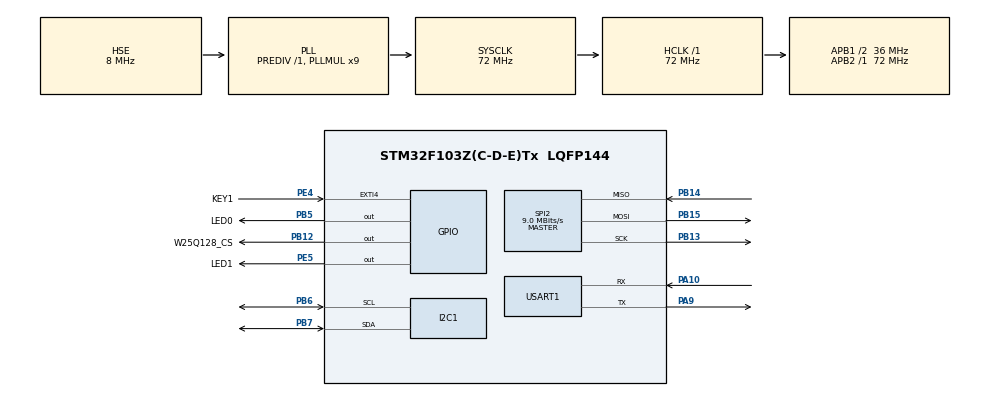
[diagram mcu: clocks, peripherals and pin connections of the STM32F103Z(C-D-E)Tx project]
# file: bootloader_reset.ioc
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Mcu.Family=STM32F1
Mcu.Name=STM32F103Z(C-D-E)Tx
Mcu.Package=LQFP144
NVIC.EXTI4_IRQn=true\:4\:0\:true\:false\:true\:true\:true\:true
NVIC.PriorityGroup=NVIC_PRIORITYGROUP_4
NVIC.USART1_IRQn=true\:5\:0\:true\:false\:true\:true\:true\:true
OSC_IN.Mode=HSE-External-Oscillator
OSC_IN.Signal=RCC_OSC_IN
OSC_OUT.Mode=HSE-External-Oscillator
OSC_OUT.Signal=RCC_OSC_OUT
PA10.Mode=Asynchronous
PA10.Signal=USART1_RX
PA13.Mode=Serial_Wire
PA13.Signal=SYS_JTMS-SWDIO
PA14.Mode=Serial_Wire
PA14.Signal=SYS_JTCK-SWCLK
PA9.Mode=Asynchronous
PA9.Signal=USART1_TX
PB12.GPIO_Label=W25Q128_CS
PB12.GPIO_Speed=GPIO_SPEED_FREQ_HIGH
PB12.PinState=GPIO_PIN_SET
PB12.Signal=GPIO_Output
PB13.Mode=Full_Duplex_Master
PB13.Signal=SPI2_SCK
PB14.Mode=Full_Duplex_Master
PB14.Signal=SPI2_MISO
PB15.Mode=Full_Duplex_Master
PB15.Signal=SPI2_MOSI
PB5.GPIO_Label=LED0
PB5.GPIO_Speed=GPIO_SPEED_FREQ_HIGH
PB5.PinState=GPIO_PIN_SET
PB5.Signal=GPIO_Output
PB6.Mode=I2C
PB6.Signal=I2C1_SCL
PB7.Mode=I2C
PB7.Signal=I2C1_SDA
PC14-OSC32_IN.Mode=LSE-External-Oscillator
PC14-OSC32_IN.Signal=RCC_OSC32_IN
PC15-OSC32_OUT.Mode=LSE-External-Oscillator
PC15-OSC32_OUT.Signal=RCC_OSC32_OUT
PE4.GPIO_Label=KEY1
PE4.GPIO_ModeDefaultEXTI=GPIO_MODE_IT_FALLING
PE4.GPIO_PuPd=GPIO_PULLUP
PE4.Signal=GPXTI4
PE5.GPIO_Label=LED1
PE5.GPIO_Speed=GPIO_SPEED_FREQ_HIGH
PE5.PinState=GPIO_PIN_SET
PE5.Signal=GPIO_Output
ProjectManager.HeapSize=0x200
ProjectManager.StackSize=0x400
ProjectManager.TargetToolchain=MDK-ARM V5.32
RCC.AHBFreq_Value=72000000
RCC.APB1CLKDivider=RCC_HCLK_DIV2
RCC.APB1Freq_Value=36000000
RCC.APB1TimFreq_Value=72000000
RCC.APB2Freq_Value=72000000
RCC.APB2TimFreq_Value=72000000
RCC.HCLKFreq_Value=72000000
RCC.PLLMUL=RCC_PLL_MUL9
RCC.PLLSourceVirtual=RCC_PLLSOURCE_HSE
RCC.SYSCLKFreq_VALUE=72000000
RCC.SYSCLKSource=RCC_SYSCLKSOURCE_PLLCLK
RCC.USBFreq_Value=72000000
SPI2.BaudRatePrescaler=SPI_BAUDRATEPRESCALER_4
SPI2.CalculateBaudRate=9.0 MBits/s
SPI2.Direction=SPI_DIRECTION_2LINES
SPI2.Mode=SPI_MODE_MASTER
SPI2.VirtualType=VM_MASTER
USART1.VirtualMode=VM_ASYNC
board=custom

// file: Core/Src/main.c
/* USER CODE BEGIN Header */
/**
 ******************************************************************************
 * @file           : main.c
 * @brief          : Main program body
 ******************************************************************************
 * @attention
 *
 * Copyright (c) 2026 STMicroelectronics.
 * All rights reserved.
 *
 * This software is licensed under terms that can be found in the LICENSE file
 * in the root directory of this software component.
 * If no LICENSE file comes with this software, it is provided AS-IS.
 *
 ******************************************************************************
 */
/* USER CODE END Header */
#include "main.h"
#include "i2c.h"
#include "spi.h"
#include "usart.h"
#include "gpio.h"

/* USER CODE BEGIN Includes */
// #include "App_bootloader.h"
#include "App_reset.h"
/* USER CODE END Includes */

void SystemClock_Config(void);

/* USER CODE BEGIN 0 */
#define RESET_ADDR 0x4000
/* USER CODE END 0 */

int main(void)
{

  /* USER CODE BEGIN 1 */
  // 重定向中断向量表
  SCB->VTOR = FLASH_BASE | RESET_ADDR;
  // 打开中断
  __enable_irq();
  /* USER CODE END 1 */

  /* MCU Configuration--------------------------------------------------------*/

  /* Reset of all peripherals, Initializes the Flash interface and the Systick. */
  HAL_Init();

  /* Configure the system clock */
  SystemClock_Config();

  /* Initialize all configured peripherals */
  MX_GPIO_Init();
  MX_USART1_UART_Init();
  MX_I2C1_Init();
  MX_SPI2_Init();
  /* USER CODE BEGIN 2 */

  // 出厂设置的默认程序
  App_bootloader_init();

  /* USER CODE END 2 */

  /* Infinite loop */
  /* USER CODE BEGIN WHILE */
  while (1)
  {

    App_bootloader_work();
    // 点亮LED0，表示正在运行出厂默认程序
    HAL_GPIO_WritePin(LED0_GPIO_Port, LED0_Pin, GPIO_PIN_RESET);
    HAL_Delay(100);
    HAL_GPIO_WritePin(LED0_GPIO_Port, LED0_Pin, GPIO_PIN_SET);
    HAL_Delay(100);
    /* USER CODE END WHILE */

  }
}

void SystemClock_Config(void)
{
  RCC_OscInitTypeDef RCC_OscInitStruct = {0};
  RCC_ClkInitTypeDef RCC_ClkInitStruct = {0};

  /** Initializes the RCC Oscillators according to the specified parameters
   * in the RCC_OscInitTypeDef structure.
   */
  RCC_OscInitStruct.OscillatorType = RCC_OSCILLATORTYPE_HSE;
  RCC_OscInitStruct.HSEState = RCC_HSE_ON;
  RCC_OscInitStruct.HSEPredivValue = RCC_HSE_PREDIV_DIV1;
  RCC_OscInitStruct.HSIState = RCC_HSI_ON;
  RCC_OscInitStruct.PLL.PLLState = RCC_PLL_ON;
  RCC_OscInitStruct.PLL.PLLSource = RCC_PLLSOURCE_HSE;
  RCC_OscInitStruct.PLL.PLLMUL = RCC_PLL_MUL9;
  if (HAL_RCC_OscConfig(&RCC_OscInitStruct) != HAL_OK)
  {
    Error_Handler();
  }

  /** Initializes the CPU, AHB and APB buses clocks
   */
  RCC_ClkInitStruct.ClockType = RCC_CLOCKTYPE_HCLK | RCC_CLOCKTYPE_SYSCLK | RCC_CLOCKTYPE_PCLK1 | RCC_CLOCKTYPE_PCLK2;
  RCC_ClkInitStruct.SYSCLKSource = RCC_SYSCLKSOURCE_PLLCLK;
  RCC_ClkInitStruct.AHBCLKDivider = RCC_SYSCLK_DIV1;
  RCC_ClkInitStruct.APB1CLKDivider = RCC_HCLK_DIV2;
  RCC_ClkInitStruct.APB2CLKDivider = RCC_HCLK_DIV1;

  if (HAL_RCC_ClockConfig(&RCC_ClkInitStruct, FLASH_LATENCY_2) != HAL_OK)
  {
    Error_Handler();
  }
}

void Error_Handler(void)
{
  __disable_irq();
  while (1)
  {
  }
}
